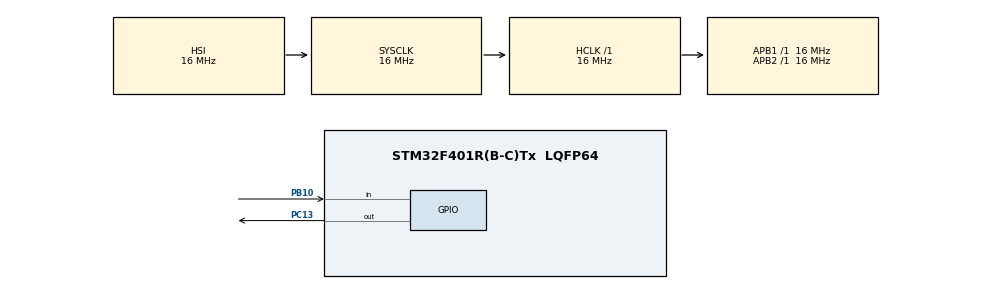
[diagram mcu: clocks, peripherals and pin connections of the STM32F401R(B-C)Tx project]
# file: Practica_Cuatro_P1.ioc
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Mcu.Family=STM32F4
Mcu.Name=STM32F401R(B-C)Tx
Mcu.Package=LQFP64
NVIC.PriorityGroup=NVIC_PRIORITYGROUP_4
PB10.GPIO_PuPd=GPIO_PULLUP
PB10.Signal=GPIO_Input
PC13-ANTI_TAMP.Signal=GPIO_Output
ProjectManager.HeapSize=0x200
ProjectManager.StackSize=0x400
ProjectManager.TargetToolchain=STM32CubeIDE
RCC.AHBFreq_Value=16000000
RCC.APB1Freq_Value=16000000
RCC.APB2Freq_Value=16000000
RCC.CortexFreq_Value=16000000
RCC.HSE_VALUE=25000000
RCC.HSI_VALUE=16000000
RCC.LSE_VALUE=32768
RCC.SYSCLKFreq_VALUE=16000000
RCC.VCOOutputFreq_Value=192000000
board=custom

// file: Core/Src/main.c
/* USER CODE BEGIN Header */
/**
  ******************************************************************************
  * @file           : main.c
  * @brief          : Main program body
  ******************************************************************************
  * @attention
  *
  * Copyright (c) 2023 STMicroelectronics.
  * All rights reserved.
  *
  * This software is licensed under terms that can be found in the LICENSE file
  * in the root directory of this software component.
  * If no LICENSE file comes with this software, it is provided AS-IS.
  *
  ******************************************************************************
  */
/* USER CODE END Header */
#include "main.h"
#include "gpio.h"

/* USER CODE BEGIN Includes */
#include "API_delay.h"
#include "stm32f4xx_hal.h"
/* USER CODE END Includes */

/* USER CODE BEGIN PTD */
typedef enum
{
	BUTTON_UP,
	BUTTON_FALLING,
	BUTTON_DOWN,
	BUTTON_RISING,
} debounceState_t;
/* USER CODE END PTD */

/* USER CODE BEGIN PD */
#define TIEMPO_RETARDO 40 //tiempo de anti-rebote

/* USER CODE END PD */

/* USER CODE BEGIN PV */
static debounceState_t estadoActual;
static delay_t tiempoRetardo;

/* USER CODE END PV */

void SystemClock_Config(void);
/* USER CODE BEGIN PFP */
/*Prototipo de funciones*/
// carga el estado inicial
void debounceFSM_Init()
{
	delayInit(&tiempoRetardo, TIEMPO_RETARDO);
	estadoActual = BUTTON_UP;
}

//Lee las entradas, resuelve la lógica de transición de estados y actualiza las salidas
void debounceFSM_Update()
{
	switch (estadoActual)
	{
	case BUTTON_UP: if(HAL_GPIO_ReadPin(GPIOB, GPIO_PIN_10))
						{
							estadoActual= BUTTON_FALLING;
							delayRead(&tiempoRetardo);
						}
	break;
	case BUTTON_FALLING: if (delayRead(&tiempoRetardo))
						{
							if(!HAL_GPIO_ReadPin(GPIOB, GPIO_PIN_10)){estadoActual =BUTTON_UP;}

							else
							{
								button_Pressed();
								estadoActual =BUTTON_DOWN;
							}
						}

	break;
	case BUTTON_DOWN: if(!HAL_GPIO_ReadPin(GPIOB, GPIO_PIN_10))
							{
								estadoActual= BUTTON_RISING;
								delayRead(&tiempoRetardo);
							}
	break;
	case BUTTON_RISING: if (delayRead(&tiempoRetardo))
							{
								if(HAL_GPIO_ReadPin(GPIOB, GPIO_PIN_10))
								{
								estadoActual =BUTTON_DOWN;

								}
								else
								{
								button_Released();
								estadoActual =BUTTON_UP;
								}
							}

	break;
	default: estadoActual= BUTTON_UP;

	}

}

///debe encender el LED
void button_Pressed(void)
{

	HAL_GPIO_WritePin(GPIOC, GPIO_PIN_13, GPIO_PIN_SET);

}

// debe apagar el LED
void button_Released(void)
{

	HAL_GPIO_WritePin(GPIOC, GPIO_PIN_13, GPIO_PIN_RESET);

}

/* USER CODE END PFP */

int main(void)
{

  /* MCU Configuration--------------------------------------------------------*/

  /* Reset of all peripherals, Initializes the Flash interface and the Systick. */
  HAL_Init();

  /* Configure the system clock */
  SystemClock_Config();

  /* Initialize all configured peripherals */
  MX_GPIO_Init();

  /* Infinite loop */
  /* USER CODE BEGIN WHILE */
  while (1)
  {
	  debounceFSM_Update();

    /* USER CODE END WHILE */

  }
}

void SystemClock_Config(void)
{
  RCC_OscInitTypeDef RCC_OscInitStruct = {0};
  RCC_ClkInitTypeDef RCC_ClkInitStruct = {0};

  /** Configure the main internal regulator output voltage
  */
  __HAL_RCC_PWR_CLK_ENABLE();
  __HAL_PWR_VOLTAGESCALING_CONFIG(PWR_REGULATOR_VOLTAGE_SCALE2);

  /** Initializes the RCC Oscillators according to the specified parameters
  * in the RCC_OscInitTypeDef structure.
  */
  RCC_OscInitStruct.OscillatorType = RCC_OSCILLATORTYPE_HSI;
  RCC_OscInitStruct.HSIState = RCC_HSI_ON;
  RCC_OscInitStruct.HSICalibrationValue = RCC_HSICALIBRATION_DEFAULT;
  RCC_OscInitStruct.PLL.PLLState = RCC_PLL_NONE;
  if (HAL_RCC_OscConfig(&RCC_OscInitStruct) != HAL_OK)
  {
    Error_Handler();
  }

  /** Initializes the CPU, AHB and APB buses clocks
  */
  RCC_ClkInitStruct.ClockType = RCC_CLOCKTYPE_HCLK|RCC_CLOCKTYPE_SYSCLK
                              |RCC_CLOCKTYPE_PCLK1|RCC_CLOCKTYPE_PCLK2;
  RCC_ClkInitStruct.SYSCLKSource = RCC_SYSCLKSOURCE_HSI;
  RCC_ClkInitStruct.AHBCLKDivider = RCC_SYSCLK_DIV1;
  RCC_ClkInitStruct.APB1CLKDivider = RCC_HCLK_DIV1;
  RCC_ClkInitStruct.APB2CLKDivider = RCC_HCLK_DIV1;

  if (HAL_RCC_ClockConfig(&RCC_ClkInitStruct, FLASH_LATENCY_0) != HAL_OK)
  {
    Error_Handler();
  }
}

void Error_Handler(void)
{
  __disable_irq();
  while (1)
  {
  }
}
